# BL808 register map
File version: 0.1
Registers are access not given, no defined reset value unless marked. A register's access mark holds for its fields unless they carry their own. Offsets are from the block's base; [hi:lo] are bit positions; {n}, {i} and the like mark numbered series.

## DSP2_MISC
Base 0x30010000
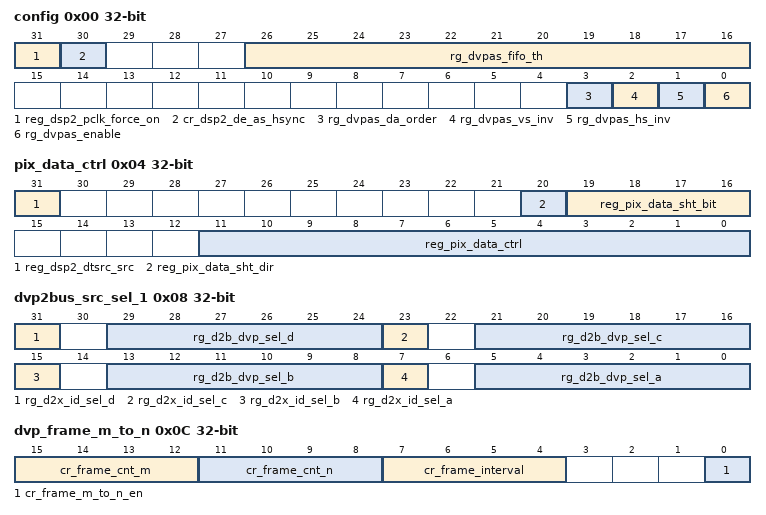
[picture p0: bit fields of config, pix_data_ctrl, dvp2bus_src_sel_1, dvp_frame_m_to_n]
0x00 config
  [31] reg_dsp2_pclk_force_on rw, [30] cr_dsp2_de_as_hsync rw, [26:16] rg_dvpas_fifo_th rw, [3] rg_dvpas_da_order rw, [2] rg_dvpas_vs_inv rw, [1] rg_dvpas_hs_inv rw, [0] rg_dvpas_enable rw
0x04 pix_data_ctrl
  [31] reg_dsp2_dtsrc_src rw, [20] reg_pix_data_sht_dir rw, [19:16] reg_pix_data_sht_bit rw, [11:0] reg_pix_data_ctrl rw
0x08 dvp2bus_src_sel_1
  [31] rg_d2x_id_sel_d rw, [29:24] rg_d2b_dvp_sel_d rw, [23] rg_d2x_id_sel_c rw, [21:16] rg_d2b_dvp_sel_c rw, [15] rg_d2x_id_sel_b rw, [13:8] rg_d2b_dvp_sel_b rw, [7] rg_d2x_id_sel_a rw, [5:0] rg_d2b_dvp_sel_a rw
0x0C dvp_frame_m_to_n
  [15:12] cr_frame_cnt_m rw, [11:8] cr_frame_cnt_n rw, [7:4] cr_frame_interval rw, [0] cr_frame_m_to_n_en rw
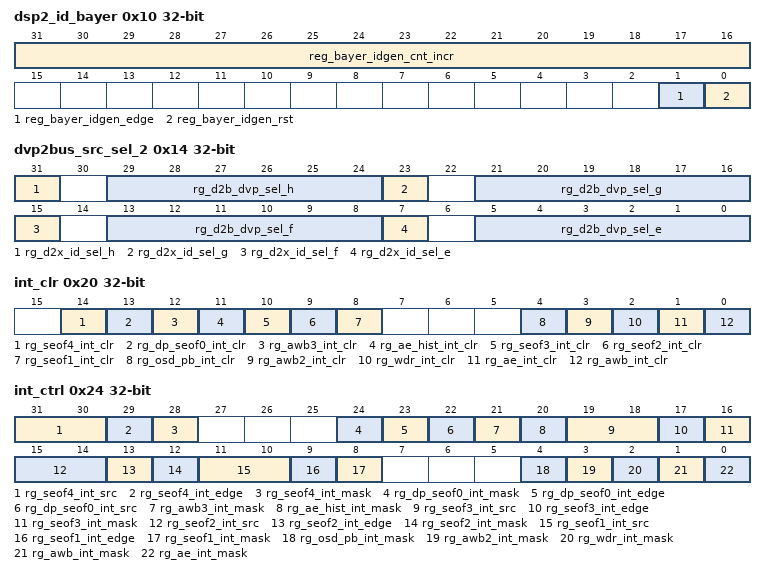
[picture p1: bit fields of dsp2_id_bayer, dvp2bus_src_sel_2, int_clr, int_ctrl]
0x10 dsp2_id_bayer
  [31:16] reg_bayer_idgen_cnt_incr rw, [1] reg_bayer_idgen_edge rw, [0] reg_bayer_idgen_rst write-once
0x14 dvp2bus_src_sel_2
  [31] rg_d2x_id_sel_h rw, [29:24] rg_d2b_dvp_sel_h rw, [23] rg_d2x_id_sel_g rw, [21:16] rg_d2b_dvp_sel_g rw, [15] rg_d2x_id_sel_f rw, [13:8] rg_d2b_dvp_sel_f rw, [7] rg_d2x_id_sel_e rw, [5:0] rg_d2b_dvp_sel_e rw
0x20 int_clr
  [14] rg_seof4_int_clr write-once, [13] rg_dp_seof0_int_clr write-once, [12] rg_awb3_int_clr write-once, [11] rg_ae_hist_int_clr write-once, [10] rg_seof3_int_clr write-once, [9] rg_seof2_int_clr write-once, [8] rg_seof1_int_clr write-once, [4] rg_osd_pb_int_clr write-once, [3] rg_awb2_int_clr write-once, [2] rg_wdr_int_clr write-once, [1] rg_ae_int_clr write-once, [0] rg_awb_int_clr write-once
0x24 int_ctrl
  [31:30] rg_seof4_int_src rw, [29] rg_seof4_int_edge rw, [28] rg_seof4_int_mask rw, [24] rg_dp_seof0_int_mask rw, [23] rg_dp_seof0_int_edge rw, [22] rg_dp_seof0_int_src rw, [21] rg_awb3_int_mask rw, [20] rg_ae_hist_int_mask rw, [19:18] rg_seof3_int_src rw, [17] rg_seof3_int_edge rw, [16] rg_seof3_int_mask rw, [15:14] rg_seof2_int_src rw, [13] rg_seof2_int_edge rw, [12] rg_seof2_int_mask rw, [11:10] rg_seof1_int_src rw, [9] rg_seof1_int_edge rw, [8] rg_seof1_int_mask rw, [4] rg_osd_pb_int_mask rw, [3] rg_awb2_int_mask rw, [2] rg_wdr_int_mask rw, [1] rg_awb_int_mask rw, [0] rg_ae_int_mask rw
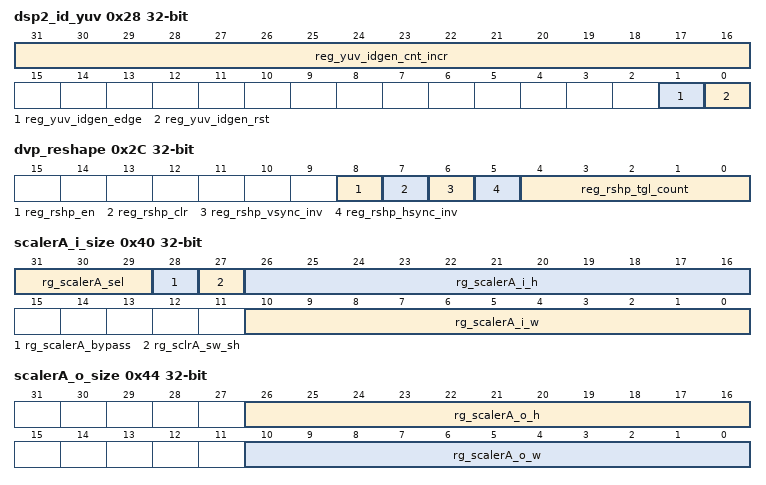
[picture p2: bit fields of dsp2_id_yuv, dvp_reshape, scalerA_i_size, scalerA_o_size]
0x28 dsp2_id_yuv
  [31:16] reg_yuv_idgen_cnt_incr rw, [1] reg_yuv_idgen_edge rw, [0] reg_yuv_idgen_rst write-once
0x2C dvp_reshape
  [8] reg_rshp_en rw, [7] reg_rshp_clr write-once, [6] reg_rshp_vsync_inv rw, [5] reg_rshp_hsync_inv rw, [4:0] reg_rshp_tgl_count rw
0x40 scalerA_i_size
  [31:29] rg_scalerA_sel rw, [28] rg_scalerA_bypass rw, [27] rg_sclrA_sw_sh write-once, [26:16] rg_scalerA_i_h rw, [10:0] rg_scalerA_i_w rw
0x44 scalerA_o_size
  [26:16] rg_scalerA_o_h rw, [10:0] rg_scalerA_o_w rw
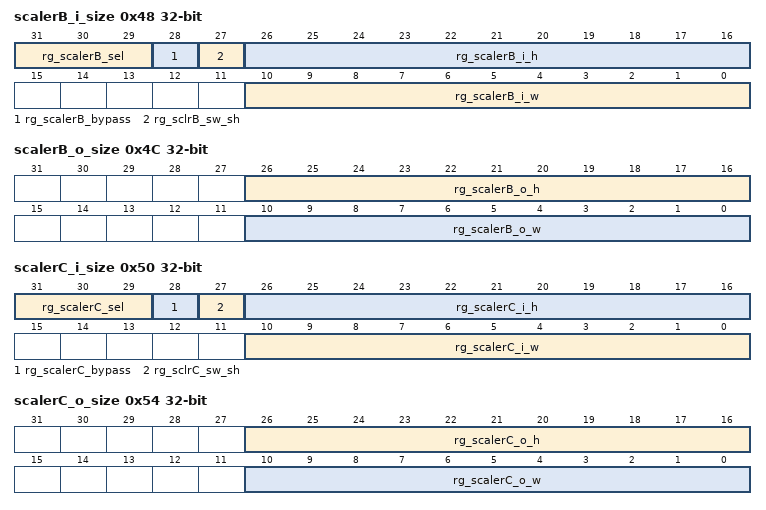
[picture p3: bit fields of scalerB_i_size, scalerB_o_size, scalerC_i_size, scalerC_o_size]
0x48 scalerB_i_size
  [31:29] rg_scalerB_sel rw, [28] rg_scalerB_bypass rw, [27] rg_sclrB_sw_sh write-once, [26:16] rg_scalerB_i_h rw, [10:0] rg_scalerB_i_w rw
0x4C scalerB_o_size
  [26:16] rg_scalerB_o_h rw, [10:0] rg_scalerB_o_w rw
0x50 scalerC_i_size
  [31:29] rg_scalerC_sel rw, [28] rg_scalerC_bypass rw, [27] rg_sclrC_sw_sh write-once, [26:16] rg_scalerC_i_h rw, [10:0] rg_scalerC_i_w rw
0x54 scalerC_o_size
  [26:16] rg_scalerC_o_h rw, [10:0] rg_scalerC_o_w rw
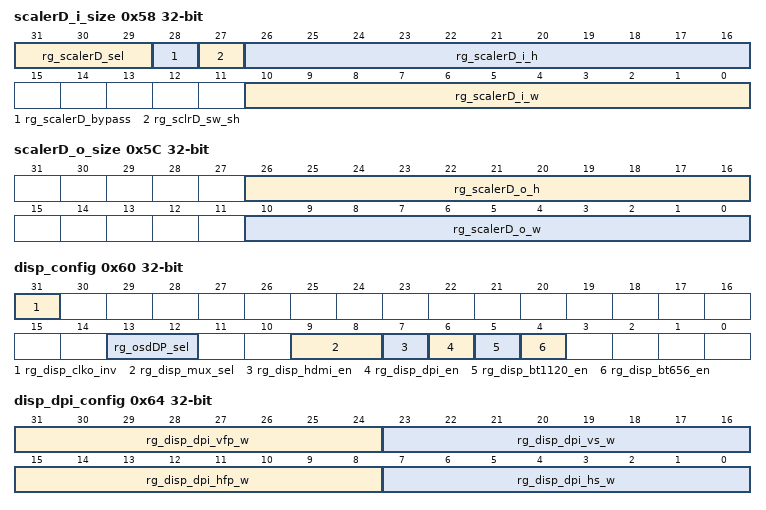
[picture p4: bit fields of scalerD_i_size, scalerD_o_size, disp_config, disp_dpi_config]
0x58 scalerD_i_size
  [31:29] rg_scalerD_sel rw, [28] rg_scalerD_bypass rw, [27] rg_sclrD_sw_sh write-once, [26:16] rg_scalerD_i_h rw, [10:0] rg_scalerD_i_w rw
0x5C scalerD_o_size
  [26:16] rg_scalerD_o_h rw, [10:0] rg_scalerD_o_w rw
0x60 disp_config
  [31] rg_disp_clko_inv rw, [13:12] rg_osdDP_sel rw, [9:8] rg_disp_mux_sel rw, [7] rg_disp_hdmi_en rw, [6] rg_disp_dpi_en rw, [5] rg_disp_bt1120_en rw, [4] rg_disp_bt656_en rw
0x64 disp_dpi_config rw
  [31:24] rg_disp_dpi_vfp_w, [23:16] rg_disp_dpi_vs_w, [15:8] rg_disp_dpi_hfp_w, [7:0] rg_disp_dpi_hs_w
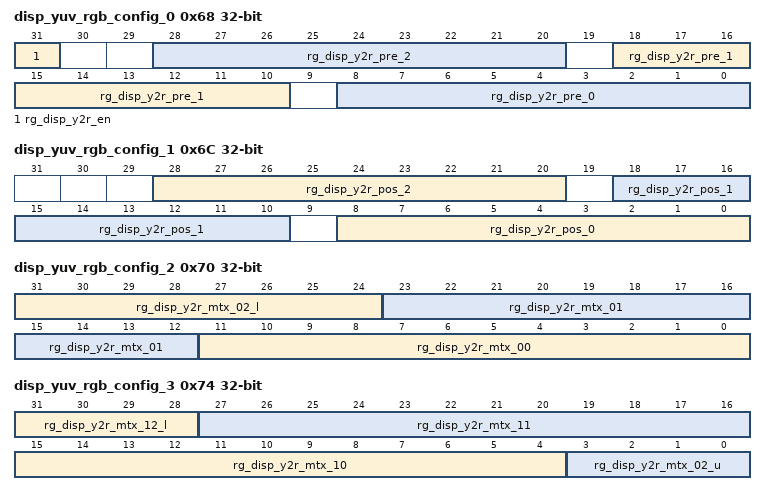
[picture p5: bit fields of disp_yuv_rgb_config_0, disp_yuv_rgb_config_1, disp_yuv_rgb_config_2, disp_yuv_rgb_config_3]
0x68 disp_yuv_rgb_config_0
  [31] rg_disp_y2r_en rw, [28:20] rg_disp_y2r_pre_2 rw, [18:10] rg_disp_y2r_pre_1 rw, [8:0] rg_disp_y2r_pre_0 rw
0x6C disp_yuv_rgb_config_1
  [28:20] rg_disp_y2r_pos_2 rw, [18:10] rg_disp_y2r_pos_1 rw, [8:0] rg_disp_y2r_pos_0 rw
0x70 disp_yuv_rgb_config_2 rw
  [31:24] rg_disp_y2r_mtx_02_l, [23:12] rg_disp_y2r_mtx_01, [11:0] rg_disp_y2r_mtx_00
0x74 disp_yuv_rgb_config_3 rw
  [31:28] rg_disp_y2r_mtx_12_l, [27:16] rg_disp_y2r_mtx_11, [15:4] rg_disp_y2r_mtx_10, [3:0] rg_disp_y2r_mtx_02_u
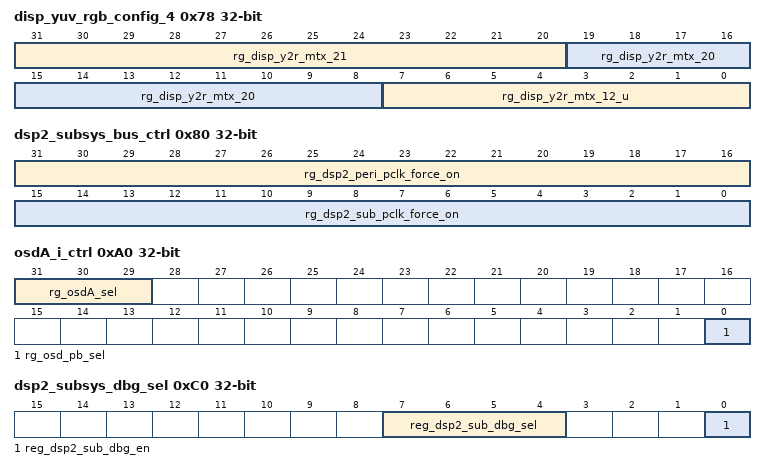
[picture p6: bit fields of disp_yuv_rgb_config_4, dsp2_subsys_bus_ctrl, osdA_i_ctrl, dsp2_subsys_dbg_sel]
0x78 disp_yuv_rgb_config_4 rw
  [31:20] rg_disp_y2r_mtx_21, [19:8] rg_disp_y2r_mtx_20, [7:0] rg_disp_y2r_mtx_12_u
0x7C disp_yuv_rgb_config_5
  [11:0] rg_disp_y2r_mtx_22 rw
0x80 dsp2_subsys_bus_ctrl rw
  [31:16] rg_dsp2_peri_pclk_force_on, [15:0] rg_dsp2_sub_pclk_force_on
0xA0 osdA_i_ctrl
  [31:29] rg_osdA_sel rw, [0] rg_osd_pb_sel rw
0xA4 osdB_i_ctrl
  [31:29] rg_osdB_sel rw
0xA8 osdC_i_ctrl
  [31:29] rg_osdC_sel rw
0xAC osdD_i_ctrl
  [31:29] rg_osdD_sel rw
0xC0 dsp2_subsys_dbg_sel
  [7:4] reg_dsp2_sub_dbg_sel rw, [0] reg_dsp2_sub_dbg_en rw
0xFC DSP2_MISC_Dummy rw
  [31:0] dummy_reg
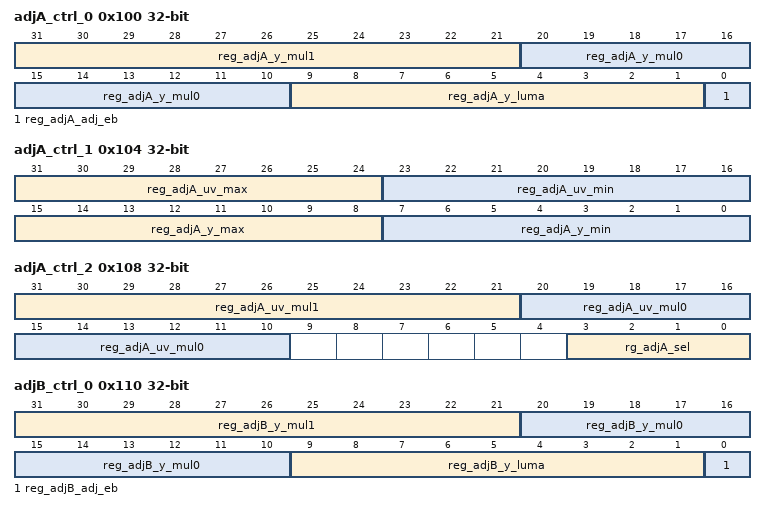
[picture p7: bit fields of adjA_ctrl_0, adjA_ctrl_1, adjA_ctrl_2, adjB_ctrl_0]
0x100 adjA_ctrl_0 rw
  [31:21] reg_adjA_y_mul1, [20:10] reg_adjA_y_mul0, [9:1] reg_adjA_y_luma, [0] reg_adjA_adj_eb
0x104 adjA_ctrl_1 rw
  [31:24] reg_adjA_uv_max, [23:16] reg_adjA_uv_min, [15:8] reg_adjA_y_max, [7:0] reg_adjA_y_min
0x108 adjA_ctrl_2
  [31:21] reg_adjA_uv_mul1 rw, [20:10] reg_adjA_uv_mul0 rw, [3:0] rg_adjA_sel rw
0x110 adjB_ctrl_0 rw
  [31:21] reg_adjB_y_mul1, [20:10] reg_adjB_y_mul0, [9:1] reg_adjB_y_luma, [0] reg_adjB_adj_eb
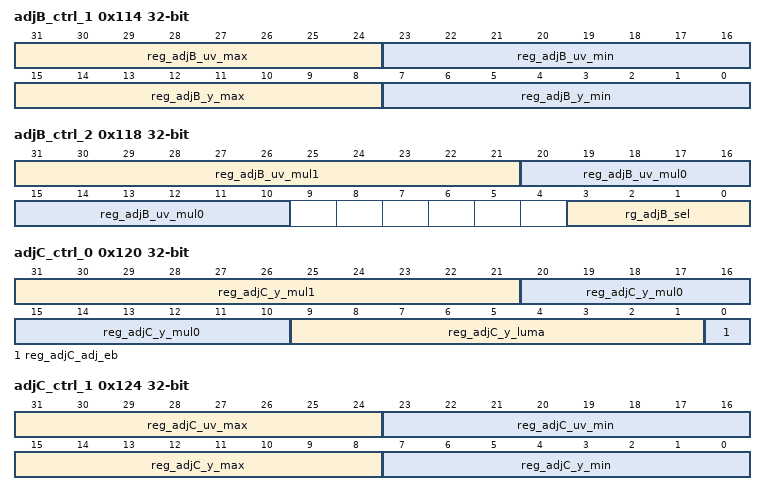
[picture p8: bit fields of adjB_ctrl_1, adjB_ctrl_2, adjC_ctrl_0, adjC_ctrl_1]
0x114 adjB_ctrl_1 rw
  [31:24] reg_adjB_uv_max, [23:16] reg_adjB_uv_min, [15:8] reg_adjB_y_max, [7:0] reg_adjB_y_min
0x118 adjB_ctrl_2
  [31:21] reg_adjB_uv_mul1 rw, [20:10] reg_adjB_uv_mul0 rw, [3:0] rg_adjB_sel rw
0x120 adjC_ctrl_0 rw
  [31:21] reg_adjC_y_mul1, [20:10] reg_adjC_y_mul0, [9:1] reg_adjC_y_luma, [0] reg_adjC_adj_eb
0x124 adjC_ctrl_1 rw
  [31:24] reg_adjC_uv_max, [23:16] reg_adjC_uv_min, [15:8] reg_adjC_y_max, [7:0] reg_adjC_y_min
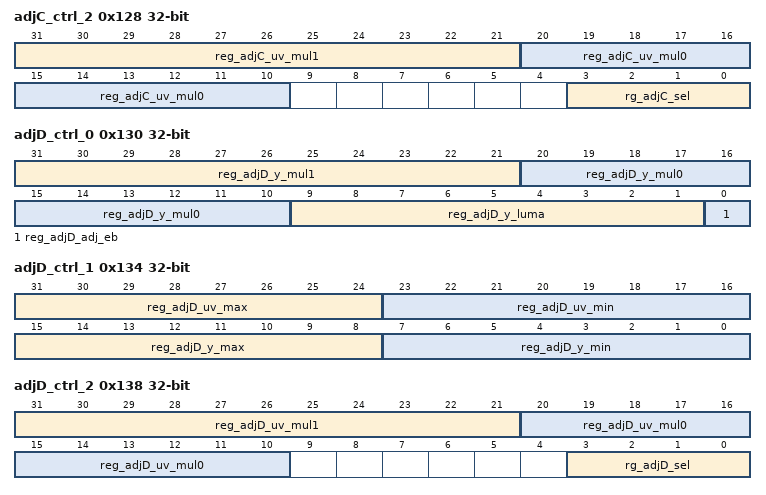
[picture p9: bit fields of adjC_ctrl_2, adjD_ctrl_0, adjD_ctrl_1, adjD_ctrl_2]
0x128 adjC_ctrl_2
  [31:21] reg_adjC_uv_mul1 rw, [20:10] reg_adjC_uv_mul0 rw, [3:0] rg_adjC_sel rw
0x130 adjD_ctrl_0 rw
  [31:21] reg_adjD_y_mul1, [20:10] reg_adjD_y_mul0, [9:1] reg_adjD_y_luma, [0] reg_adjD_adj_eb
0x134 adjD_ctrl_1 rw
  [31:24] reg_adjD_uv_max, [23:16] reg_adjD_uv_min, [15:8] reg_adjD_y_max, [7:0] reg_adjD_y_min
0x138 adjD_ctrl_2
  [31:21] reg_adjD_uv_mul1 rw, [20:10] reg_adjD_uv_mul0 rw, [3:0] rg_adjD_sel rw
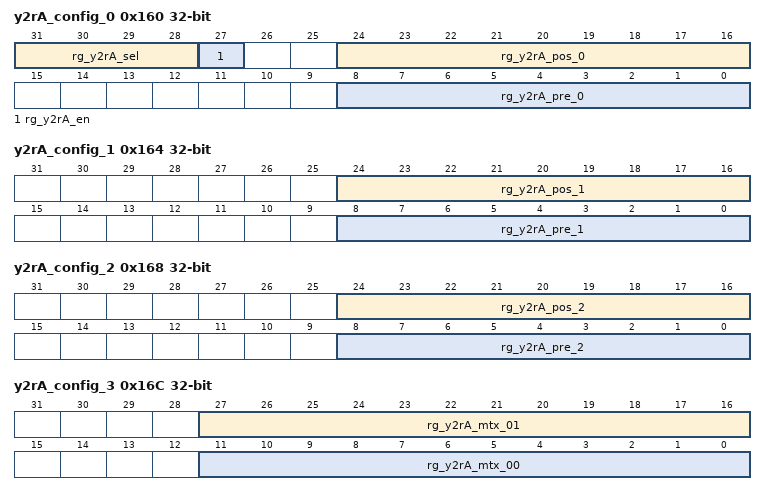
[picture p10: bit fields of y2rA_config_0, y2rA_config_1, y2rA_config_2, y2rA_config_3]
0x160 y2rA_config_0
  [31:28] rg_y2rA_sel rw, [27] rg_y2rA_en rw, [24:16] rg_y2rA_pos_0 rw, [8:0] rg_y2rA_pre_0 rw
0x164 y2rA_config_1
  [24:16] rg_y2rA_pos_1 rw, [8:0] rg_y2rA_pre_1 rw
0x168 y2rA_config_2
  [24:16] rg_y2rA_pos_2 rw, [8:0] rg_y2rA_pre_2 rw
0x16C y2rA_config_3
  [27:16] rg_y2rA_mtx_01 rw, [11:0] rg_y2rA_mtx_00 rw
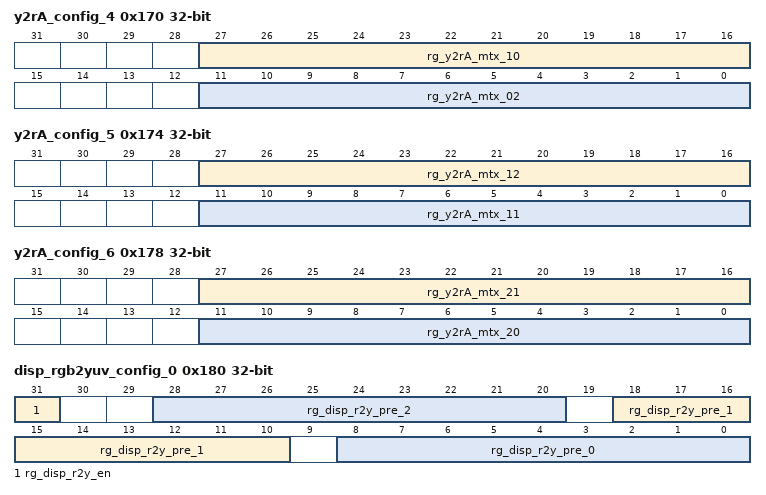
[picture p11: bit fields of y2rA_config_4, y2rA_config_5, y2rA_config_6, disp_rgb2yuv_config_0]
0x170 y2rA_config_4
  [27:16] rg_y2rA_mtx_10 rw, [11:0] rg_y2rA_mtx_02 rw
0x174 y2rA_config_5
  [27:16] rg_y2rA_mtx_12 rw, [11:0] rg_y2rA_mtx_11 rw
0x178 y2rA_config_6
  [27:16] rg_y2rA_mtx_21 rw, [11:0] rg_y2rA_mtx_20 rw
0x17C y2rA_config_7
  [11:0] rg_y2rA_mtx_22 rw
0x180 disp_rgb2yuv_config_0
  [31] rg_disp_r2y_en rw, [28:20] rg_disp_r2y_pre_2 rw, [18:10] rg_disp_r2y_pre_1 rw, [8:0] rg_disp_r2y_pre_0 rw
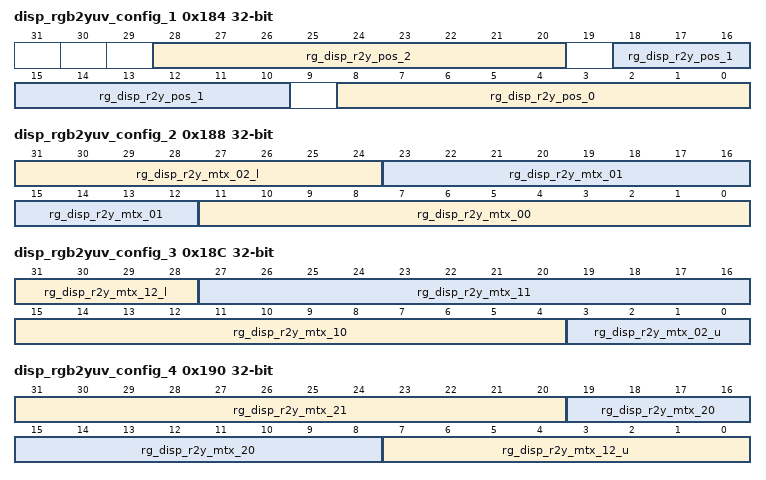
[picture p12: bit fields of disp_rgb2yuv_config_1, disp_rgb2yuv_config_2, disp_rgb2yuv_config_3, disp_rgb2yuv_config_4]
0x184 disp_rgb2yuv_config_1
  [28:20] rg_disp_r2y_pos_2 rw, [18:10] rg_disp_r2y_pos_1 rw, [8:0] rg_disp_r2y_pos_0 rw
0x188 disp_rgb2yuv_config_2 rw
  [31:24] rg_disp_r2y_mtx_02_l, [23:12] rg_disp_r2y_mtx_01, [11:0] rg_disp_r2y_mtx_00
0x18C disp_rgb2yuv_config_3 rw
  [31:28] rg_disp_r2y_mtx_12_l, [27:16] rg_disp_r2y_mtx_11, [15:4] rg_disp_r2y_mtx_10, [3:0] rg_disp_r2y_mtx_02_u
0x190 disp_rgb2yuv_config_4 rw
  [31:20] rg_disp_r2y_mtx_21, [19:8] rg_disp_r2y_mtx_20, [7:0] rg_disp_r2y_mtx_12_u
0x194 disp_rgb2yuv_config_5
  [11:0] rg_disp_r2y_mtx_22 rw
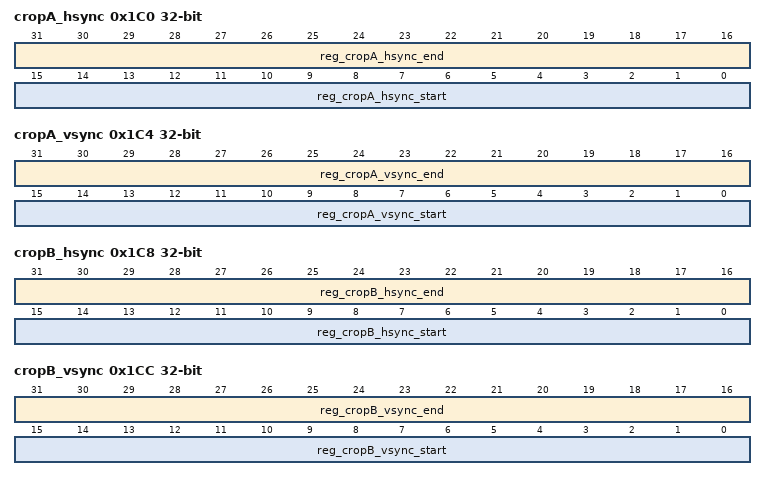
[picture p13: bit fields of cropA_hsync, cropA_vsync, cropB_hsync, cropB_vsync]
0x1C0 cropA_hsync rw
  [31:16] reg_cropA_hsync_end, [15:0] reg_cropA_hsync_start
0x1C4 cropA_vsync rw
  [31:16] reg_cropA_vsync_end, [15:0] reg_cropA_vsync_start
0x1C8 cropB_hsync rw
  [31:16] reg_cropB_hsync_end, [15:0] reg_cropB_hsync_start
0x1CC cropB_vsync rw
  [31:16] reg_cropB_vsync_end, [15:0] reg_cropB_vsync_start
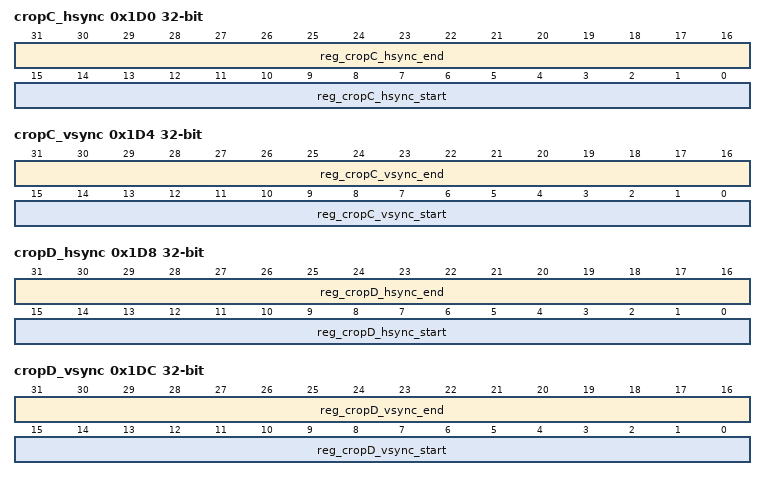
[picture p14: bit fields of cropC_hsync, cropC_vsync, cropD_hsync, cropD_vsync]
0x1D0 cropC_hsync rw
  [31:16] reg_cropC_hsync_end, [15:0] reg_cropC_hsync_start
0x1D4 cropC_vsync rw
  [31:16] reg_cropC_vsync_end, [15:0] reg_cropC_vsync_start
0x1D8 cropD_hsync rw
  [31:16] reg_cropD_hsync_end, [15:0] reg_cropD_hsync_start
0x1DC cropD_vsync rw
  [31:16] reg_cropD_vsync_end, [15:0] reg_cropD_vsync_start
0x1E0 crop_enable
  [3] reg_cropD_enable rw, [2] reg_cropC_enable rw, [1] reg_cropB_enable rw, [0] reg_cropA_enable rw
0x1FC disp_gma_cfg
  [2] reg_dp_gma_ch2_en rw, [1] reg_dp_gma_ch1_en rw, [0] reg_dp_gma_ch0_en rw
0x200 disp_gma_curve_00 rw
  [8n+7:8n] reg_dp_gma_curve_{n:02} (n=0..3)
0x204 disp_gma_curve_04 rw
  [8n-25:8n-32] reg_dp_gma_curve_{n:02} (n=4..7)
0x208 disp_gma_curve_08 rw
  [31:24] reg_dp_gma_curve_0b, [23:16] reg_dp_gma_curve_0a, [15:8] reg_dp_gma_curve_09, [7:0] reg_dp_gma_curve_08
{0x20C+0x10*i} disp_gma_curve_{i}c rw (i=0..9)
  [31:24] reg_dp_gma_curve_{i}f, [23:16] reg_dp_gma_curve_{i}e, [15:8] reg_dp_gma_curve_{i}d, [7:0] reg_dp_gma_curve_{i}c
0x210 disp_gma_curve_10 rw
  [8n-73:8n-80] reg_dp_gma_curve_{n} (n=10..13)
0x214 disp_gma_curve_14 rw
  [8n-105:8n-112] reg_dp_gma_curve_{n} (n=14..17)
0x218 disp_gma_curve_18 rw
  [31:24] reg_dp_gma_curve_1b, [23:16] reg_dp_gma_curve_1a, [15:8] reg_dp_gma_curve_19, [7:0] reg_dp_gma_curve_18
0x220 disp_gma_curve_20 rw
  [8n-153:8n-160] reg_dp_gma_curve_{n} (n=20..23)
0x224 disp_gma_curve_24 rw
  [8n-185:8n-192] reg_dp_gma_curve_{n} (n=24..27)
0x228 disp_gma_curve_28 rw
  [31:24] reg_dp_gma_curve_2b, [23:16] reg_dp_gma_curve_2a, [15:8] reg_dp_gma_curve_29, [7:0] reg_dp_gma_curve_28
0x230 disp_gma_curve_30 rw
  [8n-233:8n-240] reg_dp_gma_curve_{n} (n=30..33)
0x234 disp_gma_curve_34 rw
  [8n-265:8n-272] reg_dp_gma_curve_{n} (n=34..37)
0x238 disp_gma_curve_38 rw
  [31:24] reg_dp_gma_curve_3b, [23:16] reg_dp_gma_curve_3a, [15:8] reg_dp_gma_curve_39, [7:0] reg_dp_gma_curve_38
0x240 disp_gma_curve_40 rw
  [8n-313:8n-320] reg_dp_gma_curve_{n} (n=40..43)
0x244 disp_gma_curve_44 rw
  [8n-345:8n-352] reg_dp_gma_curve_{n} (n=44..47)
0x248 disp_gma_curve_48 rw
  [31:24] reg_dp_gma_curve_4b, [23:16] reg_dp_gma_curve_4a, [15:8] reg_dp_gma_curve_49, [7:0] reg_dp_gma_curve_48
0x250 disp_gma_curve_50 rw
  [8n-393:8n-400] reg_dp_gma_curve_{n} (n=50..53)
0x254 disp_gma_curve_54 rw
  [8n-425:8n-432] reg_dp_gma_curve_{n} (n=54..57)
0x258 disp_gma_curve_58 rw
  [31:24] reg_dp_gma_curve_5b, [23:16] reg_dp_gma_curve_5a, [15:8] reg_dp_gma_curve_59, [7:0] reg_dp_gma_curve_58
0x260 disp_gma_curve_60 rw
  [8n-473:8n-480] reg_dp_gma_curve_{n} (n=60..63)
0x264 disp_gma_curve_64 rw
  [8n-505:8n-512] reg_dp_gma_curve_{n} (n=64..67)
0x268 disp_gma_curve_68 rw
  [31:24] reg_dp_gma_curve_6b, [23:16] reg_dp_gma_curve_6a, [15:8] reg_dp_gma_curve_69, [7:0] reg_dp_gma_curve_68
0x270 disp_gma_curve_70 rw
  [8n-553:8n-560] reg_dp_gma_curve_{n} (n=70..73)
0x274 disp_gma_curve_74 rw
  [8n-585:8n-592] reg_dp_gma_curve_{n} (n=74..77)
0x278 disp_gma_curve_78 rw
  [31:24] reg_dp_gma_curve_7b, [23:16] reg_dp_gma_curve_7a, [15:8] reg_dp_gma_curve_79, [7:0] reg_dp_gma_curve_78
0x280 disp_gma_curve_80 rw
  [8n-633:8n-640] reg_dp_gma_curve_{n} (n=80..83)
0x284 disp_gma_curve_84 rw
  [8n-665:8n-672] reg_dp_gma_curve_{n} (n=84..87)
0x288 disp_gma_curve_88 rw
  [31:24] reg_dp_gma_curve_8b, [23:16] reg_dp_gma_curve_8a, [15:8] reg_dp_gma_curve_89, [7:0] reg_dp_gma_curve_88
0x290 disp_gma_curve_90 rw
  [8n-713:8n-720] reg_dp_gma_curve_{n} (n=90..93)
0x294 disp_gma_curve_94 rw
  [8n-745:8n-752] reg_dp_gma_curve_{n} (n=94..97)
0x298 disp_gma_curve_98 rw
  [31:24] reg_dp_gma_curve_9b, [23:16] reg_dp_gma_curve_9a, [15:8] reg_dp_gma_curve_99, [7:0] reg_dp_gma_curve_98
0x2A0 disp_gma_curve_a0 rw
  [8n+7:8n] reg_dp_gma_curve_a{n} (n=0..3)
0x2A4 disp_gma_curve_a4 rw
  [8n-25:8n-32] reg_dp_gma_curve_a{n} (n=4..7)
0x2A8 disp_gma_curve_a8 rw
  [31:24] reg_dp_gma_curve_ab, [23:16] reg_dp_gma_curve_aa, [15:8] reg_dp_gma_curve_a9, [7:0] reg_dp_gma_curve_a8
0x2AC disp_gma_curve_ac rw
  [31:24] reg_dp_gma_curve_af, [23:16] reg_dp_gma_curve_ae, [15:8] reg_dp_gma_curve_ad, [7:0] reg_dp_gma_curve_ac
0x2B0 disp_gma_curve_b0 rw
  [8n+7:8n] reg_dp_gma_curve_b{n} (n=0..3)
0x2B4 disp_gma_curve_b4 rw
  [8n-25:8n-32] reg_dp_gma_curve_b{n} (n=4..7)
0x2B8 disp_gma_curve_b8 rw
  [31:24] reg_dp_gma_curve_bb, [23:16] reg_dp_gma_curve_ba, [15:8] reg_dp_gma_curve_b9, [7:0] reg_dp_gma_curve_b8
0x2BC disp_gma_curve_bc rw
  [31:24] reg_dp_gma_curve_bf, [23:16] reg_dp_gma_curve_be, [15:8] reg_dp_gma_curve_bd, [7:0] reg_dp_gma_curve_bc
0x2C0 disp_gma_curve_c0 rw
  [8n+7:8n] reg_dp_gma_curve_c{n} (n=0..3)
0x2C4 disp_gma_curve_c4 rw
  [8n-25:8n-32] reg_dp_gma_curve_c{n} (n=4..7)
0x2C8 disp_gma_curve_c8 rw
  [31:24] reg_dp_gma_curve_cb, [23:16] reg_dp_gma_curve_ca, [15:8] reg_dp_gma_curve_c9, [7:0] reg_dp_gma_curve_c8
0x2CC disp_gma_curve_cc rw
  [31:24] reg_dp_gma_curve_cf, [23:16] reg_dp_gma_curve_ce, [15:8] reg_dp_gma_curve_cd, [7:0] reg_dp_gma_curve_cc
0x2D0 disp_gma_curve_d0 rw
  [8n+7:8n] reg_dp_gma_curve_d{n} (n=0..3)
0x2D4 disp_gma_curve_d4 rw
  [8n-25:8n-32] reg_dp_gma_curve_d{n} (n=4..7)
0x2D8 disp_gma_curve_d8 rw
  [31:24] reg_dp_gma_curve_db, [23:16] reg_dp_gma_curve_da, [15:8] reg_dp_gma_curve_d9, [7:0] reg_dp_gma_curve_d8
0x2DC disp_gma_curve_dc rw
  [31:24] reg_dp_gma_curve_df, [23:16] reg_dp_gma_curve_de, [15:8] reg_dp_gma_curve_dd, [7:0] reg_dp_gma_curve_dc
0x2E0 disp_gma_curve_e0 rw
  [8n+7:8n] reg_dp_gma_curve_e{n} (n=0..3)
0x2E4 disp_gma_curve_e4 rw
  [8n-25:8n-32] reg_dp_gma_curve_e{n} (n=4..7)
0x2E8 disp_gma_curve_e8 rw
  [31:24] reg_dp_gma_curve_eb, [23:16] reg_dp_gma_curve_ea, [15:8] reg_dp_gma_curve_e9, [7:0] reg_dp_gma_curve_e8
0x2EC disp_gma_curve_ec rw
  [31:24] reg_dp_gma_curve_ef, [23:16] reg_dp_gma_curve_ee, [15:8] reg_dp_gma_curve_ed, [7:0] reg_dp_gma_curve_ec
0x2F0 disp_gma_curve_f0 rw
  [8n+7:8n] reg_dp_gma_curve_f{n} (n=0..3)
0x2F4 disp_gma_curve_f4 rw
  [8n-25:8n-32] reg_dp_gma_curve_f{n} (n=4..7)
0x2F8 disp_gma_curve_f8 rw
  [31:24] reg_dp_gma_curve_fb, [23:16] reg_dp_gma_curve_fa, [15:8] reg_dp_gma_curve_f9, [7:0] reg_dp_gma_curve_f8
0x2FC disp_gma_curve_fc rw
  [31:24] reg_dp_gma_curve_ff, [23:16] reg_dp_gma_curve_fe, [15:8] reg_dp_gma_curve_fd, [7:0] reg_dp_gma_curve_fc
